# MSPM0G5187 register map
Vendor: Texas Instruments; File version: Revised: 2025-07-22 15:38:34
CPU: CM0 r0p1, little endian, MPU, no FPU, 3 interrupt priority bits
Registers are 32-bit, read-write, reset 0x0 unless marked. A register's access mark holds for its fields unless they carry their own. Offsets are from the block's base; [hi:lo] are bit positions; lines under a group give offsets from that group; {n}, {i} and the like mark numbered series; 'fields as' and 'values as' point back to an identical list.

## NPU — PERIPHERALREGION
Base 0x408FF000
{0x800+0x18*i} NPU_GPRCM[{i}] (i=0..0) group
  0x00 NPU_PWREN — Power enable
    [0] ENABLE — Enable the power
      0=DISABLE (Disable Power); 1=ENABLE (Enable Power)
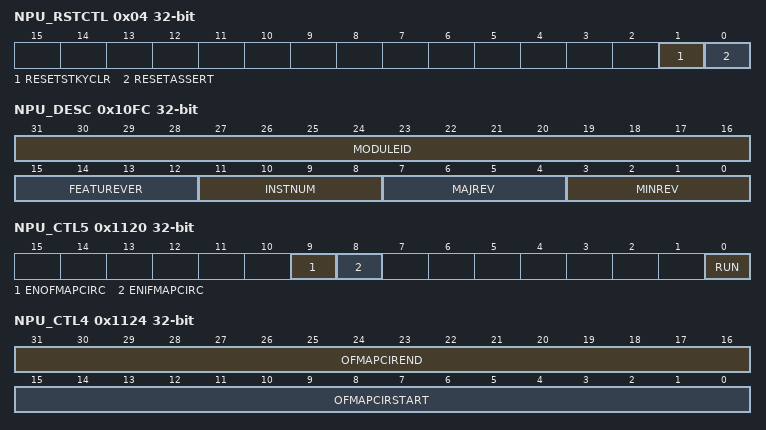
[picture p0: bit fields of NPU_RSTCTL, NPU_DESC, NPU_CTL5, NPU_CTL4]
  0x04 NPU_RSTCTL wo — Reset Control
    [1] RESETSTKYCLR — Clear the RESETSTKY bit in the STAT register
      0=NOP (Writing 0 has no effect); 1=CLR (Clear reset sticky bit)
    [0] RESETASSERT — Assert reset to the peripheral
      0=NOP (Writing 0 has no effect); 1=ASSERT (Assert reset)
  0x14 NPU_STAT ro — Status Register
    [16] RESETSTKY — This bit indicates, if the peripheral was reset, since this bit was cleared by RESETSTKYCLR in the RSTCTL register
      0=NORES (The peripheral has not been reset since this bit was last cleared by RESETSTKYCLR in the RSTCTL register); 1=RESET (The peripheral was reset since the last bit clear)
{0x1020+0x2C*i} NPU_INT_EVENT[{i}] (i=0..0) group
  0x00 NPU_IIDX ro — Interrupt index
    [7:0] STAT — Interrupt index status
      0=NO_INTR (No interrupt pending); 1=DONE (Done indication interrupt)
  0x08 NPU_IMASK — Interrupt mask
    [0] DONE — DONE interrupt
      0=CLR (Disable Event); 1=SET (Enable Event)
  0x10 NPU_RIS ro — Raw interrupt status
    fields as NPU_INT_EVENT[0].NPU_IMASK
  0x18 NPU_MIS ro — Masked interrupt status
    fields as NPU_INT_EVENT[0].NPU_IMASK
  0x20 NPU_ISET wo — Interrupt set
    fields as NPU_INT_EVENT[0].NPU_IMASK
  0x28 NPU_ICLR wo — Interrupt clear
    fields as NPU_INT_EVENT[0].NPU_IMASK
0x10E0 NPU_EVT_MODE ro reset 0x1 — 'Event Mode'
  [1:0] INT0_CFG — 'Event line mode select for event corresponding to [IPSTANDARD.INT_EVENT][0]'
    0=DISABLE ('The interrupt or event line is disabled.'); 1=SOFTWARE ('The interrupt or event line is in software mode. Software must clear the RIS.'); 2=HARDWARE ('The interrupt or event line is in hardware mode. The hardware (another module) clears automatically the associated RIS flag.')
0x10FC NPU_DESC ro — Module Description Register
  [31:16] MODULEID — specifies module id
  [15:12] FEATUREVER — specifies feature version info
  [11:8] INSTNUM — specifies module instance number
  [7:4] MAJREV — specifies major revision id
  [3:0] MINREV — specifies minor revision id
0x1120 NPU_CTL5 — CTL5 register
  [9] ENOFMAPCIRC — Enable circular addressing on output feature map read address.
    0=DISABLE (Disable circular buffering on the output feature map); 1=ENABLE (Enable circular buffering on the output feature map)
  [8] ENIFMAPCIRC — Enable circular addressing on input feature map read address.
    0=DISABLE; 1=ENABLE (Enable circular buffering on the input feature map)
  [0] RUN — Start the accelerator. Writing a 1 to this bit starts the accelerator. When the STOP instruction is executed this bit is cleared by hardware and DONE interrupt flag is set.
0x1124 NPU_CTL4
  [31:16] OFMAPCIREND — Circular buffer output feature map end address.
  [15:0] OFMAPCIRSTART — Circular buffer output feature map start address.
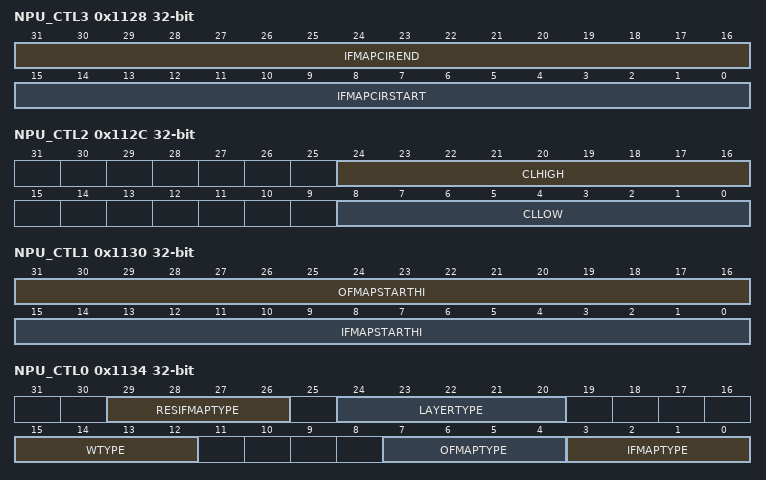
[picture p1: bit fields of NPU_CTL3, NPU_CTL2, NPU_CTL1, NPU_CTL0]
0x1128 NPU_CTL3
  [31:16] IFMAPCIREND — Circular buffer input feature map end address
  [15:0] IFMAPCIRSTART — Circular buffer input feature map start address
0x112C NPU_CTL2 — CTL2 register
  [24:16] CLHIGH — Upper clamp value
  [8:0] CLLOW — Lower clamp value
0x1130 NPU_CTL1 — CTL1 register
  [31:16] OFMAPSTARTHI — Start address (Higher 16 bits) of output feature map data.
  [15:0] IFMAPSTARTHI — Start address (Higher 16 bits) of input feature map data.
0x1134 NPU_CTL0 — CTL0 register
  [29:26] RESIFMAPTYPE — Residual Input feature map type,
    0=UNSIGNED_16BIT; 1=UNSIGNED_8BIT (Unsigned 8 bit data type); 2=UNSIGNED_4BIT (Unsigned 4 bit data type); 8=SIGNED_16BIT; 9=SIGNED_8BIT (Signed 8 bit data type); 10=SIGNED_4BIT (Signed 4 bit data type)
  [24:20] LAYERTYPE
    0=FCONV; 2=DW; 3=PW; 5=CONV; 6=FC; 7=AVGPOOL; 8=MAXPOOL; 16=FCONV_RESIDUAL; 18=DW_RESIDUAL; 19=PW_RESIDUAL; 21=CONV_RESIDUAL; 22=FC_RESIDUAL; 23=AVGPOOL_RESIDUAL; 24=MAXPOOL_RESIDUAL
  [15:12] WTYPE — Weight Type
    0=_2T (+1,-1,0); 1=BINARY (Binary data type, +1 or -1); 2=SIGNED_2BIT (Unsigned 8 bit data type); 3=SIGNED_4BIT (Signed 4 bit data type); 4=SIGNED_8BIT (Signed 8 bit data type)
  [7:4] OFMAPTYPE — Output feature map type.
    0=UNSIGNED_16BIT; 1=UNSIGNED_8BIT (Unsigned 8 bit data type); 2=UNSIGNED_4BIT (Unsigned 4 bit data type); 3=BINARY (Binary data type); 8=SIGNED_16BIT; 9=SIGNED_8BIT (Signed 8 bit data type); 10=SIGNED_4BIT (Signed 4 bit data type)
  [3:0] IFMAPTYPE — Input feature map type,
    values as OFMAPTYPE
{0x1138+0x18*i} NPU_LCREG[{i}] (i=0..0) group
  {0x0+4j} NPU_LC[{j}] (j=0..5) — Loop count registers.
    [15:0] CNT — Loop count.
0x1150 NPU_PC — Program count register
  [15:0] VALUE — Program count value.
{0x1154+0x50*i} NPU_ADDRREG[{i}] (i=0..0) group
  {0x0+4j} NPU_AREG[{j}] (j=0..19) — Address registers.
    [15:0] DATA — Data word.
{0x1710+4i} NPU_DATAIN[{i}] (i=0..1) — Input Data registers, used to load data from memory.
0x1720 NPU_DATAOUT — Output Data registers, used to store data to memory.
0x1730 NPU_SS0LOW — Scale and shift register 0, lower 32 bits.
0x1734 NPU_SS0HIGH — Scale and shift register 0, upper 32 bits.
0x1738 NPU_SS1LOW — Scale and shift register 1, lower 32 bits.
0x173C NPU_SS1HIGH — Scale and shift register 1, upper 32 bits.
0x1750 NPU_WGHT0LOW — Weight register 0, lower 32 bits.
0x1754 NPU_WGHT0HIGH — Weight register 0, upper 32 bits.
0x1758 NPU_WGHT1LOW — Weight register 1, lower 32 bits.
0x175C NPU_WGHT1HIGH — Weight register 1, upper 32 bits.
{0x1C00+0x80*i} NPU_ACCREG[{i}] (i=0..0) group
  {0x0+4j} NPU_ACCVAL[{j}] (j=0..31) — Register file data.
    [17:0] DATA — Data word.
{0x2000+0x400*i} NPU_INSTMEM[{i}] (i=0..0) group
  {0x0+4j} NPU_INSTMEM_INSTMEM[{j}] (j=0..255) — Instruction memory word.
{0x2800+0x800*i} NPU_REGFILE[{i}] (i=0..0) group
  {0x0+4j} NPU_RFDATA[{j}] (j=0..511) — Register file data.
